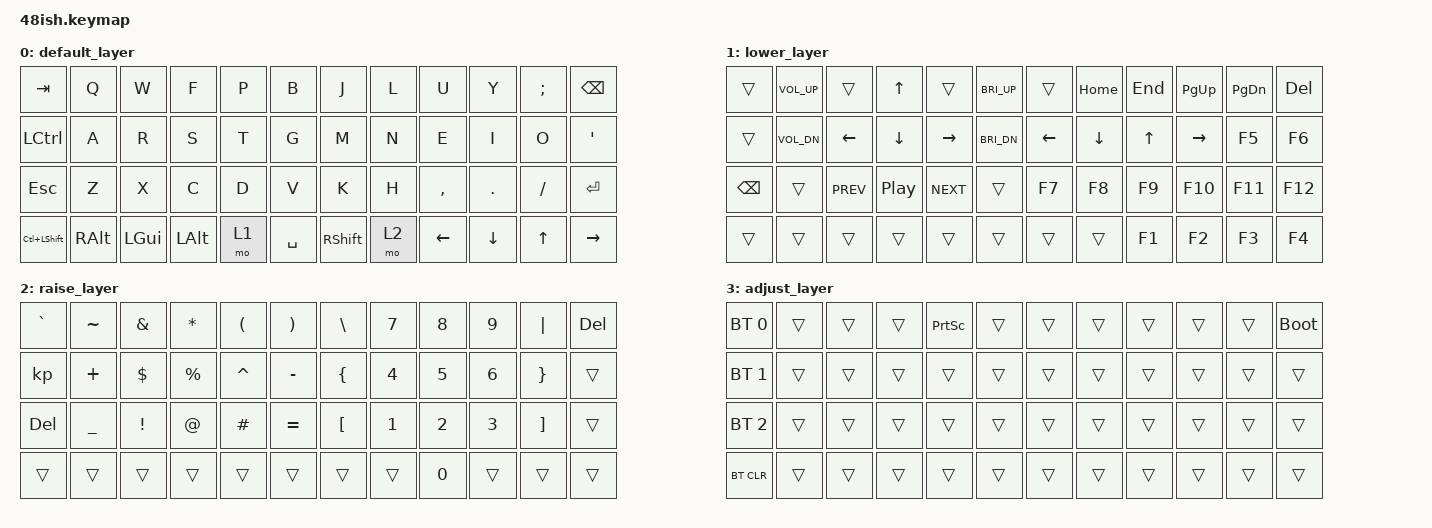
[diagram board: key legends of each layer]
#include <behaviors.dtsi>
#include <dt-bindings/zmk/keys.h>
#include <dt-bindings/zmk/bt.h>

/ {
	keymap {
		compatible = "zmk,keymap";

		default_layer { // Layer 0
			bindings = <
				&kp TAB       &kp Q     &kp W     &kp F     &kp P  &kp B      &kp J      &kp L  &kp U      &kp Y       &kp SEMI   &kp BSPC
				&kp LCTRL     &kp A     &kp R     &kp S     &kp T  &kp G      &kp M      &kp N  &kp E      &kp I       &kp O      &kp APOS
				&kp ESC       &kp Z     &kp X     &kp C     &kp D  &kp V      &kp K      &kp H  &kp COMMA  &kp PERIOD  &kp SLASH  &kp ENTER
				&kp LC(LSHIFT)&kp RALT  &kp LGUI  &kp LALT  &mo 1  &kp SPACE  &kp RSHIFT &mo 2  &kp LEFT   &kp DOWN    &kp UP     &kp RIGHT
			>;
		};

		lower_layer { // Layer 1
			bindings = <
				&trans     &kp C_VOL_UP&trans    &kp UP    &trans    &kp C_BRI_UP&trans     &kp HOME   &kp END     &kp PG_UP     &kp PG_DN     &kp DEL
				&trans     &kp C_VOL_DN&kp LEFT  &kp DOWN  &kp RIGHT &kp C_BRI_DN&kp LEFT   &kp DOWN   &kp UP      &kp RIGHT     &kp F5        &kp F6
				&kp BSPC   &trans      &kp C_PREV&kp C_PP  &kp C_NEXT&trans      &kp F7     &kp F8     &kp F9      &kp F10       &kp F11       &kp F12
				&trans     &trans      &trans    &trans    &trans    &trans      &trans     &trans     &kp F1      &kp F2        &kp F3        &kp F4
			>;
		};

		raise_layer { // Layer 2
			bindings = <
				&kp GRAVE   &kp TILDE&kp AMPS &kp STAR &kp LPAR  &kp RPAR  &kp BSLH  &kp N7      &kp N8       &kp N9         &kp PIPE       &kp DEL
				&kp         &kp PLUS &kp DLLR &kp PRCNT&kp CARET &kp MINUS &kp LBRC  &kp N4      &kp N5       &kp N6         &kp RBRC       &trans
				&kp DEL     &kp UNDER&kp EXCL &kp AT   &kp HASH  &kp EQUAL &kp LBKT  &kp N1      &kp N2       &kp N3         &kp RBKT       &trans
				&trans      &trans   &trans   &trans   &trans    &trans    &trans    &trans      &kp N0       &trans         &trans         &trans
			>;
		};

		adjust_layer { // Layer 3
			bindings = <
				&bt BT_SEL 0  &trans  &trans  &trans  &kp PSCRN &trans  &trans  &trans  &trans  &trans  &trans  &bootloader
				&bt BT_SEL 1  &trans  &trans  &trans  &trans    &trans  &trans  &trans  &trans  &trans  &trans  &trans
				&bt BT_SEL 2  &trans  &trans  &trans  &trans    &trans  &trans  &trans  &trans  &trans  &trans  &trans
				&bt BT_CLR    &trans  &trans  &trans  &trans    &trans  &trans  &trans  &trans  &trans  &trans  &trans
			>;
		};
	};

	conditional_layers {
		compatible = "zmk,conditional-layers";
		tri_layer {
			if-layers = <1 2>;
			then-layer = <3>;
		};
	};
};
